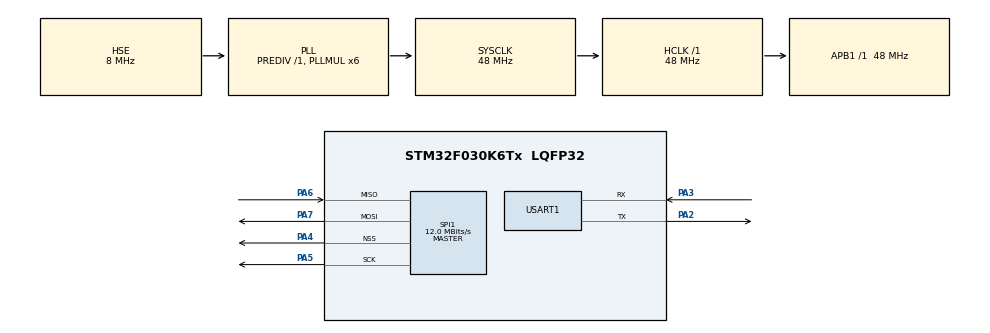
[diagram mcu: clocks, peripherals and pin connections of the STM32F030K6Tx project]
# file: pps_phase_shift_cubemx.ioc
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Dma.Request0=USART1_RX
Dma.Request1=USART1_TX
Dma.USART1_RX.0.Direction=DMA_PERIPH_TO_MEMORY
Dma.USART1_RX.0.Instance=DMA1_Channel3
Dma.USART1_RX.0.MemDataAlignment=DMA_MDATAALIGN_BYTE
Dma.USART1_RX.0.MemInc=DMA_MINC_ENABLE
Dma.USART1_RX.0.Mode=DMA_NORMAL
Dma.USART1_RX.0.PeriphDataAlignment=DMA_PDATAALIGN_BYTE
Dma.USART1_RX.0.PeriphInc=DMA_PINC_DISABLE
Dma.USART1_RX.0.Priority=DMA_PRIORITY_LOW
Dma.USART1_TX.1.Direction=DMA_MEMORY_TO_PERIPH
Dma.USART1_TX.1.Instance=DMA1_Channel2
Dma.USART1_TX.1.MemDataAlignment=DMA_MDATAALIGN_BYTE
Dma.USART1_TX.1.MemInc=DMA_MINC_ENABLE
Dma.USART1_TX.1.Mode=DMA_NORMAL
Dma.USART1_TX.1.PeriphDataAlignment=DMA_PDATAALIGN_BYTE
Dma.USART1_TX.1.PeriphInc=DMA_PINC_DISABLE
Dma.USART1_TX.1.Priority=DMA_PRIORITY_LOW
Mcu.Family=STM32F0
Mcu.Name=STM32F030K6Tx
Mcu.Package=LQFP32
NVIC.DMA1_Channel2_3_IRQn=true\:0\:0\:false\:false\:true
PA13.Mode=Serial_Wire
PA13.Signal=SYS_SWDIO
PA14.Mode=Serial_Wire
PA14.Signal=SYS_SWCLK
PA2.Mode=Asynchronous
PA2.Signal=USART1_TX
PA3.Mode=Asynchronous
PA3.Signal=USART1_RX
PA4.Mode=NSS_Signal_Hard_Output
PA4.Signal=SPI1_NSS
PA5.Mode=Full_Duplex_Master
PA5.Signal=SPI1_SCK
PA6.Mode=Full_Duplex_Master
PA6.Signal=SPI1_MISO
PA7.Mode=Full_Duplex_Master
PA7.Signal=SPI1_MOSI
PF0-OSC_IN.Mode=HSE-External-Oscillator
PF0-OSC_IN.Signal=RCC_OSC_IN
PF1-OSC_OUT.Mode=HSE-External-Oscillator
PF1-OSC_OUT.Signal=RCC_OSC_OUT
ProjectManager.HeapSize=0x200
ProjectManager.StackSize=0x400
ProjectManager.TargetToolchain=SW4STM32
RCC.AHBFreq_Value=48000000
RCC.APB1Freq_Value=48000000
RCC.APB1TimFreq_Value=48000000
RCC.HCLKFreq_Value=48000000
RCC.HSIState=RCC_HSI_ON
RCC.PLLMUL=RCC_PLL_MUL6
RCC.PLLSourceVirtual=RCC_PLLSOURCE_HSE
RCC.SYSCLKFreq_VALUE=48000000
RCC.SYSCLKSource=RCC_SYSCLKSOURCE_PLLCLK
SPI1.BaudRatePrescaler=SPI_BAUDRATEPRESCALER_4
SPI1.CalculateBaudRate=12.0 MBits/s
SPI1.Mode=SPI_MODE_MASTER
SPI1.VirtualNSS=VM_NSSHARD
board=pps_phase_shift_cubemx

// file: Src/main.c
/**
  ******************************************************************************
  * File Name          : main.c
  * Description        : Main program body
  ******************************************************************************
  *
  * COPYRIGHT(c) 2017 STMicroelectronics
  *
  * Redistribution and use in source and binary forms, with or without modification,
  * are permitted provided that the following conditions are met:
  *   1. Redistributions of source code must retain the above copyright notice,
  *      this list of conditions and the following disclaimer.
  *   2. Redistributions in binary form must reproduce the above copyright notice,
  *      this list of conditions and the following disclaimer in the documentation
  *      and/or other materials provided with the distribution.
  *   3. Neither the name of STMicroelectronics nor the names of its contributors
  *      may be used to endorse or promote products derived from this software
  *      without specific prior written permission.
  *
  * THIS SOFTWARE IS PROVIDED BY THE COPYRIGHT HOLDERS AND CONTRIBUTORS "AS IS"
  * AND ANY EXPRESS OR IMPLIED WARRANTIES, INCLUDING, BUT NOT LIMITED TO, THE
  * IMPLIED WARRANTIES OF MERCHANTABILITY AND FITNESS FOR A PARTICULAR PURPOSE ARE
  * DISCLAIMED. IN NO EVENT SHALL THE COPYRIGHT HOLDER OR CONTRIBUTORS BE LIABLE
  * FOR ANY DIRECT, INDIRECT, INCIDENTAL, SPECIAL, EXEMPLARY, OR CONSEQUENTIAL
  * DAMAGES (INCLUDING, BUT NOT LIMITED TO, PROCUREMENT OF SUBSTITUTE GOODS OR
  * SERVICES; LOSS OF USE, DATA, OR PROFITS; OR BUSINESS INTERRUPTION) HOWEVER
  * CAUSED AND ON ANY THEORY OF LIABILITY, WHETHER IN CONTRACT, STRICT LIABILITY,
  * OR TORT (INCLUDING NEGLIGENCE OR OTHERWISE) ARISING IN ANY WAY OUT OF THE USE
  * OF THIS SOFTWARE, EVEN IF ADVISED OF THE POSSIBILITY OF SUCH DAMAGE.
  *
  ******************************************************************************
  */
#include "main.h"
#include "stm32f0xx_hal.h"
#include "dma.h"
#include "spi.h"
#include "usart.h"
#include "gpio.h"

/* USER CODE BEGIN PV */
/* Private variables ---------------------------------------------------------*/

/* USER CODE END PV */

void SystemClock_Config(void);
void Error_Handler(void);

/* USER CODE BEGIN PFP */
/* Private function prototypes -----------------------------------------------*/

/* USER CODE END PFP */

int main(void)
{

  /* MCU Configuration----------------------------------------------------------*/

  /* Reset of all peripherals, Initializes the Flash interface and the Systick. */
  HAL_Init();

  /* Configure the system clock */
  SystemClock_Config();

  /* Initialize all configured peripherals */
  MX_GPIO_Init();
  MX_DMA_Init();
  MX_SPI1_Init();
  MX_USART1_UART_Init();

  /* Infinite loop */
  while (1)
  {

  /* USER CODE BEGIN 3 */
      extern UART_HandleTypeDef huart1;
      int a =32;
      HAL_UART_Transmit_DMA(&huart1, &a, 1);
      HAL_Delay(1000);
  }
  /* USER CODE END 3 */

}

/** System Clock Configuration
*/
void SystemClock_Config(void)
{

  RCC_OscInitTypeDef RCC_OscInitStruct;
  RCC_ClkInitTypeDef RCC_ClkInitStruct;
  RCC_PeriphCLKInitTypeDef PeriphClkInit;

    /**Initializes the CPU, AHB and APB busses clocks
    */
  RCC_OscInitStruct.OscillatorType = RCC_OSCILLATORTYPE_HSE;
  RCC_OscInitStruct.HSEState = RCC_HSE_ON;
  RCC_OscInitStruct.HSIState = RCC_HSI_ON;
  RCC_OscInitStruct.PLL.PLLState = RCC_PLL_ON;
  RCC_OscInitStruct.PLL.PLLSource = RCC_PLLSOURCE_HSE;
  RCC_OscInitStruct.PLL.PLLMUL = RCC_PLL_MUL6;
  RCC_OscInitStruct.PLL.PREDIV = RCC_PREDIV_DIV1;
  if (HAL_RCC_OscConfig(&RCC_OscInitStruct) != HAL_OK)
  {
    Error_Handler();
  }

    /**Initializes the CPU, AHB and APB busses clocks
    */
  RCC_ClkInitStruct.ClockType = RCC_CLOCKTYPE_HCLK|RCC_CLOCKTYPE_SYSCLK
                              |RCC_CLOCKTYPE_PCLK1;
  RCC_ClkInitStruct.SYSCLKSource = RCC_SYSCLKSOURCE_PLLCLK;
  RCC_ClkInitStruct.AHBCLKDivider = RCC_SYSCLK_DIV1;
  RCC_ClkInitStruct.APB1CLKDivider = RCC_HCLK_DIV1;

  if (HAL_RCC_ClockConfig(&RCC_ClkInitStruct, FLASH_LATENCY_1) != HAL_OK)
  {
    Error_Handler();
  }

  PeriphClkInit.PeriphClockSelection = RCC_PERIPHCLK_USART1;
  PeriphClkInit.Usart1ClockSelection = RCC_USART1CLKSOURCE_PCLK1;
  if (HAL_RCCEx_PeriphCLKConfig(&PeriphClkInit) != HAL_OK)
  {
    Error_Handler();
  }

    /**Configure the Systick interrupt time
    */
  HAL_SYSTICK_Config(HAL_RCC_GetHCLKFreq()/1000);

    /**Configure the Systick
    */
  HAL_SYSTICK_CLKSourceConfig(SYSTICK_CLKSOURCE_HCLK);

  /* SysTick_IRQn interrupt configuration */
  HAL_NVIC_SetPriority(SysTick_IRQn, 0, 0);
}

void Error_Handler(void)
{
  while(1)
  {
  }
}

/************************ (C) COPYRIGHT STMicroelectronics *****END OF FILE****/
